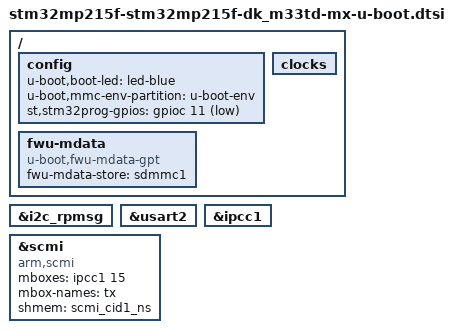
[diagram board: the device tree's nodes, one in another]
#include "stm32mp21-u-boot.dtsi"

/* USER CODE BEGIN includes */
/* USER CODE END includes */

/{

	/* USER CODE BEGIN root */

	config{
		u-boot,boot-led = "led-blue";
		u-boot,mmc-env-partition = "u-boot-env";
		st,stm32prog-gpios = <&gpioc 11 (GPIO_ACTIVE_LOW | GPIO_PULL_UP)>;
	};

	fwu-mdata{
		compatible = "u-boot,fwu-mdata-gpt";
		fwu-mdata-store = <&sdmmc1>;
	};
	/delete-node/ typec;
	/* USER CODE END root */
	clocks{

		/* USER CODE BEGIN clocks */
		/* USER CODE END clocks */
	};
};

/* USER CODE BEGIN addons */

&i2c_rpmsg {
	/delete-node/ typec@35;
};

&usart2 {
	bootph-all;
};

&ipcc1 {
	bootph-all;
	/delete-property/ clocks;
	status = "okay";
};

&scmi {
	compatible = "arm,scmi";
	#address-cells = <1>;
	#size-cells = <0>;
	mboxes = <&ipcc1 15>;
	mbox-names = "tx";
	shmem = <&scmi_cid1_ns>;
	/delete-property/ linaro,optee-channel-id;
};
/* USER CODE END addons */
